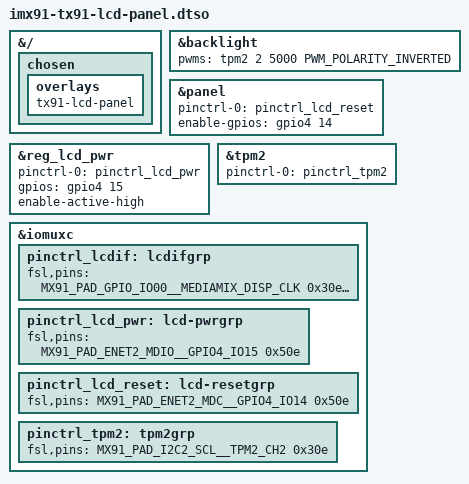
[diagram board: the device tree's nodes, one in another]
// SPDX-License-Identifier: (GPL-2.0 OR MIT)
/*
 * Copyright 2023 Lothar Waßmann <LW@KARO-electronics.de>
 *
 */

/dts-v1/;
/plugin/;

#include <dt-bindings/gpio/gpio.h>
#include <dt-bindings/pwm/pwm.h>
#include "imx91-pinfunc.h"
#include "includes/imx91-karo-backlight.dtsi"
#include "includes/imx91-karo-lcd-panel.dtsi"

&{/} {
	chosen {
		overlays {
			tx91-lcd-panel;
		};
	};
};

&backlight {
	pwms = <&tpm2 2 5000 PWM_POLARITY_INVERTED>;
};

&panel {
	pinctrl-names = "default";
	pinctrl-0 = <&pinctrl_lcd_reset>;
	enable-gpios = <&gpio4 14 GPIO_ACTIVE_HIGH>;
};

&reg_lcd_pwr {
	pinctrl-names = "default";
	pinctrl-0 = <&pinctrl_lcd_pwr>;
	gpios = <&gpio4 15 GPIO_ACTIVE_HIGH>;
	enable-active-high;
	status = "okay";
};

&tpm2 {
	pinctrl-names = "default";
	pinctrl-0 = <&pinctrl_tpm2>;
	status = "okay";
};

&iomuxc {
	pinctrl_lcdif: lcdifgrp {
		fsl,pins = <
			MX91_PAD_GPIO_IO00__MEDIAMIX_DISP_CLK		0x30e
			MX91_PAD_GPIO_IO01__MEDIAMIX_DISP_DE		0x30e
			MX91_PAD_GPIO_IO02__MEDIAMIX_DISP_VSYNC		0x30e
			MX91_PAD_GPIO_IO03__MEDIAMIX_DISP_HSYNC		0x30e
			/* BLUE */
			MX91_PAD_GPIO_IO04__MEDIAMIX_DISP_DATA0		0x30e
			MX91_PAD_GPIO_IO05__MEDIAMIX_DISP_DATA1		0x30e
			MX91_PAD_GPIO_IO06__MEDIAMIX_DISP_DATA2		0x30e
			MX91_PAD_GPIO_IO07__MEDIAMIX_DISP_DATA3		0x30e
			MX91_PAD_GPIO_IO08__MEDIAMIX_DISP_DATA4		0x30e
			MX91_PAD_GPIO_IO09__MEDIAMIX_DISP_DATA5		0x30e
			MX91_PAD_GPIO_IO10__MEDIAMIX_DISP_DATA6		0x30e
			MX91_PAD_GPIO_IO11__MEDIAMIX_DISP_DATA7		0x30e
			/* GREEN */
			MX91_PAD_GPIO_IO12__MEDIAMIX_DISP_DATA8		0x30e
			MX91_PAD_GPIO_IO13__MEDIAMIX_DISP_DATA9		0x30e
			MX91_PAD_GPIO_IO14__MEDIAMIX_DISP_DATA10	0x30e
			MX91_PAD_GPIO_IO15__MEDIAMIX_DISP_DATA11	0x30e
			MX91_PAD_GPIO_IO16__MEDIAMIX_DISP_DATA12	0x30e
			MX91_PAD_GPIO_IO17__MEDIAMIX_DISP_DATA13	0x30e
			MX91_PAD_GPIO_IO18__MEDIAMIX_DISP_DATA14	0x30e
			MX91_PAD_GPIO_IO19__MEDIAMIX_DISP_DATA15	0x30e
			/* RED */
			MX91_PAD_GPIO_IO20__MEDIAMIX_DISP_DATA16	0x30e
			MX91_PAD_GPIO_IO21__MEDIAMIX_DISP_DATA17	0x30e
			MX91_PAD_GPIO_IO22__MEDIAMIX_DISP_DATA18	0x30e
			MX91_PAD_GPIO_IO23__MEDIAMIX_DISP_DATA19	0x30e
			MX91_PAD_GPIO_IO24__MEDIAMIX_DISP_DATA20	0x30e
			MX91_PAD_GPIO_IO25__MEDIAMIX_DISP_DATA21	0x30e
			MX91_PAD_GPIO_IO26__MEDIAMIX_DISP_DATA22	0x30e
			MX91_PAD_GPIO_IO27__MEDIAMIX_DISP_DATA23	0x30e
		>;
	};

	pinctrl_lcd_pwr: lcd-pwrgrp {
		fsl,pins = <
			MX91_PAD_ENET2_MDIO__GPIO4_IO15			0x50e
		>;
	};

	pinctrl_lcd_reset: lcd-resetgrp {
		fsl,pins = <
			MX91_PAD_ENET2_MDC__GPIO4_IO14			0x50e
		>;
	};

	pinctrl_tpm2: tpm2grp {
		fsl,pins = <
			MX91_PAD_I2C2_SCL__TPM2_CH2			0x30e
		>;
	};
};
